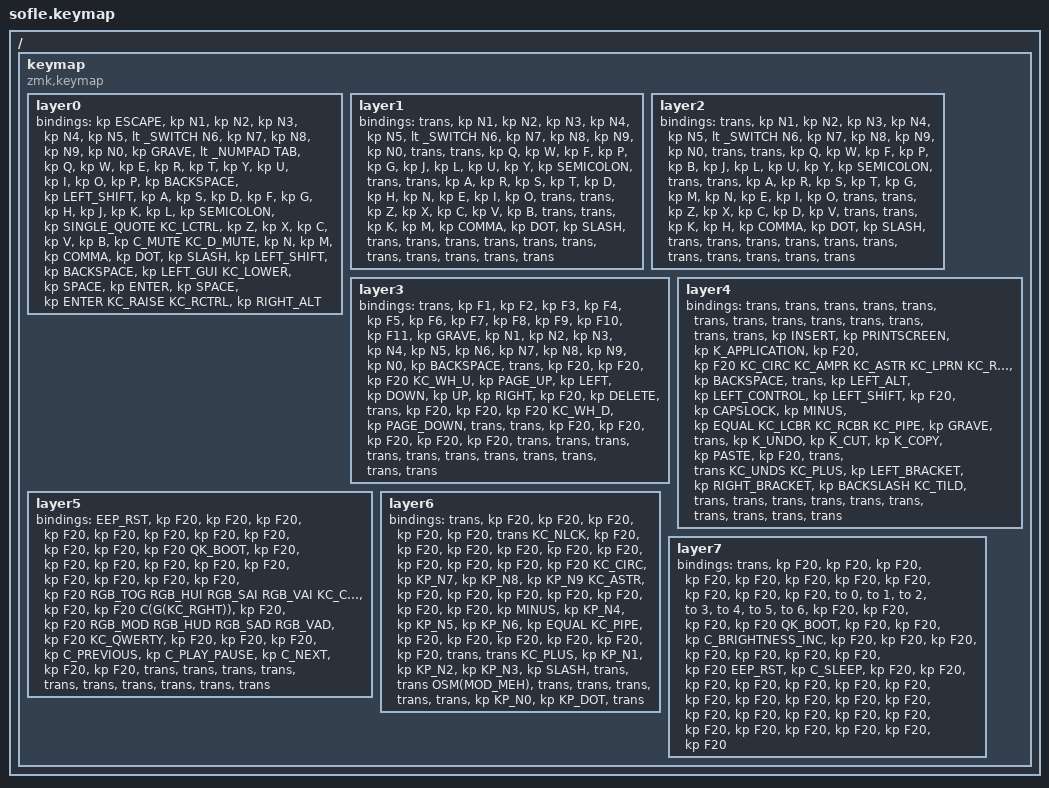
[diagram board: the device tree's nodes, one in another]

  /*
  * Copyright (c) 2020 The ZMK Contributors
  *
  * SPDX-License-Identifier: MIT
  */

  #include <behaviors.dtsi>
  #include <dt-bindings/zmk/keys.h>
  #include <dt-bindings/zmk/bt.h>
  #include <dt-bindings/zmk/ext_power.h>

  / {
    keymap {
      compatible = "zmk,keymap";
  layer0 {
          bindings = <
          &kp ESCAPE &kp N1 &kp N2 &kp N3 &kp N4 &kp N5 &lt _SWITCH N6 &kp N7 &kp N8 &kp N9 &kp N0 &kp GRAVE &lt _NUMPAD TAB &kp Q &kp W &kp E &kp R &kp T &kp Y &kp U &kp I &kp O &kp P &kp BACKSPACE &kp LEFT_SHIFT &kp A &kp S &kp D &kp F &kp G &kp H &kp J &kp K &kp L &kp SEMICOLON &kp SINGLE_QUOTE KC_LCTRL &kp Z &kp X &kp C &kp V &kp B &kp C_MUTE KC_D_MUTE &kp N &kp M &kp COMMA &kp DOT &kp SLASH &kp LEFT_SHIFT &kp BACKSPACE &kp LEFT_GUI KC_LOWER &kp SPACE &kp ENTER &kp SPACE &kp ENTER KC_RAISE KC_RCTRL &kp RIGHT_ALT
          >;
        };layer1 {
          bindings = <
          &trans &kp N1 &kp N2 &kp N3 &kp N4 &kp N5 &lt _SWITCH N6 &kp N7 &kp N8 &kp N9 &kp N0 &trans &trans &kp Q &kp W &kp F &kp P &kp G &kp J &kp L &kp U &kp Y &kp SEMICOLON &trans &trans &kp A &kp R &kp S &kp T &kp D &kp H &kp N &kp E &kp I &kp O &trans &trans &kp Z &kp X &kp C &kp V &kp B &trans &trans &kp K &kp M &kp COMMA &kp DOT &kp SLASH &trans &trans &trans &trans &trans &trans &trans &trans &trans &trans &trans
          >;
        };layer2 {
          bindings = <
          &trans &kp N1 &kp N2 &kp N3 &kp N4 &kp N5 &lt _SWITCH N6 &kp N7 &kp N8 &kp N9 &kp N0 &trans &trans &kp Q &kp W &kp F &kp P &kp B &kp J &kp L &kp U &kp Y &kp SEMICOLON &trans &trans &kp A &kp R &kp S &kp T &kp G &kp M &kp N &kp E &kp I &kp O &trans &trans &kp Z &kp X &kp C &kp D &kp V &trans &trans &kp K &kp H &kp COMMA &kp DOT &kp SLASH &trans &trans &trans &trans &trans &trans &trans &trans &trans &trans &trans
          >;
        };layer3 {
          bindings = <
          &trans &kp F1 &kp F2 &kp F3 &kp F4 &kp F5 &kp F6 &kp F7 &kp F8 &kp F9 &kp F10 &kp F11 &kp GRAVE &kp N1 &kp N2 &kp N3 &kp N4 &kp N5 &kp N6 &kp N7 &kp N8 &kp N9 &kp N0 &kp BACKSPACE &trans &kp F20 &kp F20 &kp F20 KC_WH_U &kp PAGE_UP &kp LEFT &kp DOWN &kp UP &kp RIGHT &kp F20 &kp DELETE &trans &kp F20 &kp F20 &kp F20 KC_WH_D &kp PAGE_DOWN &trans &trans &kp F20 &kp F20 &kp F20 &kp F20 &kp F20 &trans &trans &trans &trans &trans &trans &trans &trans &trans &trans &trans
          >;
        };layer4 {
          bindings = <
          &trans &trans &trans &trans &trans &trans &trans &trans &trans &trans &trans &trans &trans &kp INSERT &kp PRINTSCREEN &kp K_APPLICATION &kp F20 &kp F20 KC_CIRC KC_AMPR KC_ASTR KC_LPRN KC_RPRN &kp BACKSPACE &trans &kp LEFT_ALT &kp LEFT_CONTROL &kp LEFT_SHIFT &kp F20 &kp CAPSLOCK &kp MINUS &kp EQUAL KC_LCBR KC_RCBR KC_PIPE &kp GRAVE &trans &kp K_UNDO &kp K_CUT &kp K_COPY &kp PASTE &kp F20 &trans &trans KC_UNDS KC_PLUS &kp LEFT_BRACKET &kp RIGHT_BRACKET &kp BACKSLASH KC_TILD &trans &trans &trans &trans &trans &trans &trans &trans &trans &trans
          >;
        };layer5 {
          bindings = <
          EEP_RST &kp F20 &kp F20 &kp F20 &kp F20 &kp F20 &kp F20 &kp F20 &kp F20 &kp F20 &kp F20 &kp F20 QK_BOOT &kp F20 &kp F20 &kp F20 &kp F20 &kp F20 &kp F20 &kp F20 &kp F20 &kp F20 &kp F20 &kp F20 RGB_TOG RGB_HUI RGB_SAI RGB_VAI KC_COLEMAKDH KC_COLEMAK C(G(KC_LEFT)) &kp F20 &kp F20 C(G(KC_RGHT)) &kp F20 &kp F20 RGB_MOD RGB_HUD RGB_SAD RGB_VAD &kp F20 KC_QWERTY &kp F20 &kp F20 &kp F20 &kp C_PREVIOUS &kp C_PLAY_PAUSE &kp C_NEXT &kp F20 &kp F20 &trans &trans &trans &trans &trans &trans &trans &trans &trans &trans
          >;
        };layer6 {
          bindings = <
          &trans &kp F20 &kp F20 &kp F20 &kp F20 &kp F20 &trans KC_NLCK &kp F20 &kp F20 &kp F20 &kp F20 &kp F20 &kp F20 &kp F20 &kp F20 &kp F20 &kp F20 KC_CIRC &kp KP_N7 &kp KP_N8 &kp KP_N9 KC_ASTR &kp F20 &kp F20 &kp F20 &kp F20 &kp F20 &kp F20 &kp F20 &kp MINUS &kp KP_N4 &kp KP_N5 &kp KP_N6 &kp EQUAL KC_PIPE &kp F20 &kp F20 &kp F20 &kp F20 &kp F20 &kp F20 &trans &trans KC_PLUS &kp KP_N1 &kp KP_N2 &kp KP_N3 &kp SLASH &trans &trans OSM(MOD_MEH) &trans &trans &trans &trans &trans &kp KP_N0 &kp KP_DOT &trans
          >;
        };layer7 {
          bindings = <
          &trans &kp F20 &kp F20 &kp F20 &kp F20 &kp F20 &kp F20 &kp F20 &kp F20 &kp F20 &kp F20 &kp F20 &to 0 &to 1 &to 2 &to 3 &to 4 &to 5 &to 6 &kp F20 &kp F20 &kp F20 &kp F20 QK_BOOT &kp F20 &kp F20 &kp C_BRIGHTNESS_INC &kp F20 &kp F20 &kp F20 &kp F20 &kp F20 &kp F20 &kp F20 &kp F20 EEP_RST &kp C_SLEEP &kp F20 &kp F20 &kp F20 &kp F20 &kp F20 &kp F20 &kp F20 &kp F20 &kp F20 &kp F20 &kp F20 &kp F20 &kp F20 &kp F20 &kp F20 &kp F20 &kp F20 &kp F20 &kp F20 &kp F20 &kp F20 &kp F20 &kp F20
          >;
        };
    };
  };
  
